AUTOSAR XML (schema 00052)
package /katech/AdaptiveApplicationSwComponentTypes
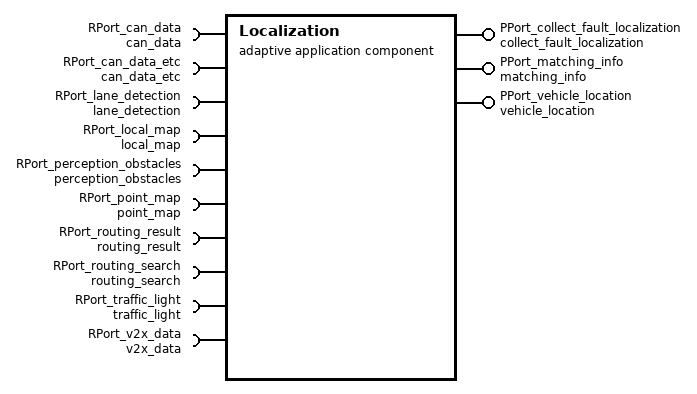
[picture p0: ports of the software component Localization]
  adaptive application sw component type Localization
    provide port PPort_collect_fault_localization: provided-interface=collect_fault_localization
    provide port PPort_matching_info: provided-interface=matching_info
    provide port PPort_vehicle_location: provided-interface=vehicle_location
    10 x require port:
      RPort_can_data: required-interface=can_data
      RPort_can_data_etc: required-interface=can_data_etc
      RPort_lane_detection: required-interface=lane_detection
      RPort_local_map: required-interface=local_map
      RPort_perception_obstacles: required-interface=perception_obstacles
      RPort_point_map: required-interface=point_map
      RPort_routing_result: required-interface=routing_result
      RPort_routing_search: required-interface=routing_search
      RPort_traffic_light: required-interface=traffic_light
      RPort_v2x_data: required-interface=v2x_data
package /katech/Executables
  executable Localization: category=APPLICATION_LEVEL, minimum-timer-granularity=1000
    root sw component prototype Localization: application-type=Localization
